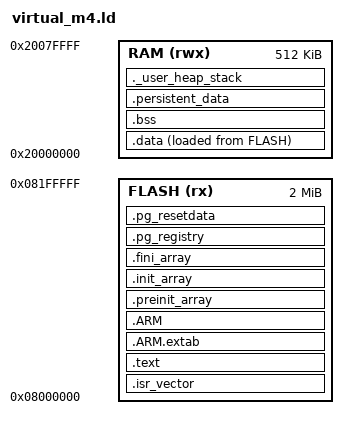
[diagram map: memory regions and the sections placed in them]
/*
 * Linker script for the virtual Cortex-M4F board.
 *
 * 0x08000000  2 MB   flash: vector table, code, read-only data, parameter
 *                    group registry and reset data, initial values of .data
 * 0x20000000  512 KB RAM: .data, .bss, config storage, stack
 * 0x40000000  4 KB   mailbox peripheral (virtual_mailbox.h)
 */

ENTRY(Reset_Handler)

MEMORY
{
    FLASH (rx)  : ORIGIN = 0x08000000, LENGTH = 2048K
    RAM (rwx)   : ORIGIN = 0x20000000, LENGTH = 512K
}

_estack = ORIGIN(RAM) + LENGTH(RAM);
_Min_Heap_Size = 0;
_Min_Stack_Size = 0x2000;

SECTIONS
{
  .isr_vector :
  {
    . = ALIGN(4);
    PROVIDE (isr_vector_table_base = .);
    KEEP(*(.isr_vector))
    . = ALIGN(4);
    PROVIDE (isr_vector_table_end = .);
  } >FLASH

  .text :
  {
    . = ALIGN(4);
    *(.text)
    *(.text*)
    *(.ram_code)
    *(.ram_code*)
    *(.rodata)
    *(.rodata*)
    *(.glue_7)
    *(.glue_7t)
    *(.eh_frame)
    KEEP (*(.init))
    KEEP (*(.fini))
    . = ALIGN(4);
    _etext = .;
  } >FLASH

  .ARM.extab : { *(.ARM.extab* .gnu.linkonce.armextab.*) } >FLASH
  .ARM :
  {
    __exidx_start = .;
    *(.ARM.exidx*)
    __exidx_end = .;
  } >FLASH

  .preinit_array :
  {
    PROVIDE_HIDDEN (__preinit_array_start = .);
    KEEP (*(.preinit_array*))
    PROVIDE_HIDDEN (__preinit_array_end = .);
  } >FLASH
  .init_array :
  {
    PROVIDE_HIDDEN (__init_array_start = .);
    KEEP (*(SORT(.init_array.*)))
    KEEP (*(.init_array*))
    PROVIDE_HIDDEN (__init_array_end = .);
  } >FLASH
  .fini_array :
  {
    PROVIDE_HIDDEN (__fini_array_start = .);
    KEEP (*(.fini_array*))
    KEEP (*(SORT(.fini_array.*)))
    PROVIDE_HIDDEN (__fini_array_end = .);
  } >FLASH

  .pg_registry :
  {
    PROVIDE_HIDDEN (__pg_registry_start = .);
    KEEP (*(.pg_registry))
    KEEP (*(SORT(.pg_registry.*)))
    PROVIDE_HIDDEN (__pg_registry_end = .);
  } >FLASH
  .pg_resetdata :
  {
    PROVIDE_HIDDEN (__pg_resetdata_start = .);
    KEEP (*(.pg_resetdata))
    PROVIDE_HIDDEN (__pg_resetdata_end = .);
  } >FLASH

  _sidata = LOADADDR(.data);
  .data :
  {
    . = ALIGN(4);
    _sdata = .;
    *(.data)
    *(.data*)
    *(.fastram_data)
    *(.fastram_data*)
    . = ALIGN(4);
    _edata = .;
  } >RAM AT> FLASH

  . = ALIGN(4);
  .bss (NOLOAD) :
  {
    _sbss = .;
    __bss_start__ = _sbss;
    *(.bss)
    *(SORT_BY_ALIGNMENT(.bss*))
    *(COMMON)
    *(.fastram_bss)
    *(SORT_BY_ALIGNMENT(.fastram_bss*))
    . = ALIGN(4);
    _ebss = .;
    __bss_end__ = _ebss;
  } >RAM

  /* Not cleared at reset, so the config survives a reboot as it would in flash. */
  .persistent_data (NOLOAD) :
  {
    . = ALIGN(8);
    __persistent_data_start__ = .;
    *(.persistent_data)
    . = ALIGN(4);
    __persistent_data_end__ = .;
  } >RAM

  _heap_stack_end = ORIGIN(RAM) + LENGTH(RAM) - 8;
  _heap_stack_begin = _heap_stack_end - _Min_Stack_Size - _Min_Heap_Size;
  . = _heap_stack_begin;
  ._user_heap_stack :
  {
    . = ALIGN(4);
    PROVIDE ( end = . );
    PROVIDE ( _end = . );
    . = . + _Min_Heap_Size;
    . = . + _Min_Stack_Size;
    . = ALIGN(4);
  } >RAM

  /DISCARD/ :
  {
    libc.a ( * )
    libm.a ( * )
    libgcc.a ( * )
  }

  .ARM.attributes 0 : { *(.ARM.attributes) }
}
